# R7FA4L1BD register map
Vendor: Renesas Electronics Corporation; Series: RA4; File version: 0.90.02
CPU: CM33 r0p4, little endian, MPU, FPU, VTOR, 4 interrupt priority bits, 96 interrupts
Registers are 32-bit, read-write, reset 0x0 unless marked. A register's access mark holds for its fields unless they carry their own. Offsets are from the block's base; [hi:lo] are bit positions; {n}, {i} and the like mark numbered series; 'fields as' and 'values as' point back to an identical list.

## UARTA
Base 0x40097000
{0x0+8i} TXBA{i} (i=0..1) 8-bit reset 0xFF — Transmit Buffer Register {i}
{0x1+8i} RXBA{i} (i=0..1) 8-bit ro reset 0xFF — Receive Buffer Register {i}
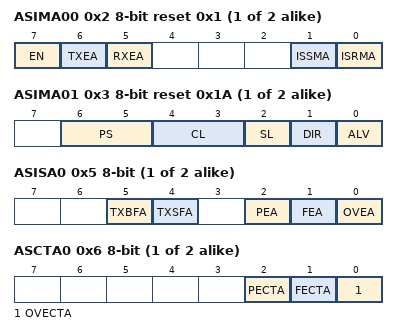
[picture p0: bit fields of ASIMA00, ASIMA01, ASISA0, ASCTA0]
{0x2+8i} ASIMA{i}0 (i=0..1) 8-bit reset 0x1 — Operation Mode Setting Register n0
  [7] EN — UART operation enable
    0=Disables the UART operation clock (resets the internal circuits); 1=Enables the UART operation clock
  [6] TXEA — Transmission enable
    0=Disables transmission (resets the transmission circuit); 1=Enables transmission
  [5] RXEA — Reception enable
    0=Disables reception (reset the reception circuit); 1=Enables reception
  [1] ISSMA — Transmit interrupt mode select
    0=The UARTAn_TXI interrupt is generated on completion of transmission; 1=The UARTAn_TXI interrupt is generated when the transmit buffer becomes empty (for continuous transmission)
  [0] ISRMA — Receive interrupt mode select
    0=The UARTAn_ERI interrupt is generated when a reception error occurs (UARTAn_RXI is not generated); 1=The UARTAn_RXI interrupt is generated when a reception error occurs (UARTAn_ERI is not generated)
{0x3+8i} ASIMA{i}1 (i=0..1) 8-bit reset 0x1A — Operation Mode Setting Register n1
  [6:5] PS — Transmission and reception parity bit setting
    0=Transmission: No parity bit is output. Reception: Data is received without parity.; 1=Transmission: 0 parity is output. Reception: Data is received with 0 parity.; 2=Transmission: Odd parity is output. Reception: Check is made for odd parity.; 3=Transmission: Even parity is output. Reception: Check is made for even parity.
  [4:3] CL — Transmission and reception character length setting
    0=Character length of data = 5 bits; 1=Setting prohibited; 2=Character length of data = 7 bits; 3=Character length of data = 8 bits
  [2] SL — Transmission stop bit length setting
    0=Stop bit length = 1 bit; 1=Stop bit length = 2 bits
  [1] DIR — Transmission and reception order setting
    0=MSB-first; 1=LSB-first
  [0] ALV — Transmission and reception level setting
    0=Positive logic (wait state = high level, start bit = low level, stop bit = high level); 1=Negative logic (wait state = low level, start bit = high level, stop bit = low level)
{0x4+8i} BRGCA{i} (i=0..1) 8-bit reset 0xFF — Baud Rate Generator Control Register {i}
{0x5+8i} ASISA{i} (i=0..1) 8-bit ro — Status Register {i}
  [5] TXBFA — Transmit buffer data flag
    0=No valid data exists in the TXBAn register; 1=Valid data exists in the TXBAn register
  [4] TXSFA — Transmit shift register data flag
    0=Data is not being transmitted; 1=Data is being transmitted
  [2] PEA — Parity error flag
    0=No error has occurred; 1=An error has occurred
  [1] FEA — Framing error flag
    0=No error has occurred; 1=An error has occurred
  [0] OVEA — Overrun error flag
    0=No error has occurred; 1=An error has occurred
{0x6+8i} ASCTA{i} (i=0..1) 8-bit — Status Clear Trigger Register {i}
  [2] PECTA — Parity error flag clear trigger
    0=Does not clear the ASISAn.PEA flag (the flag is retained); 1=Clears the ASISAn.PEA flag
  [1] FECTA — Framing error flag clear trigger
    0=Does not clear the ASISAn.FEA flag (the flag is retained); 1=Clears the ASISAn.FEA flag
  [0] OVECTA — Overrun error flag clear trigger
    0=Does not clear the ASISAn.OVEA flag (the flag is retained); 1=Clears the ASISAn.OVEA flag
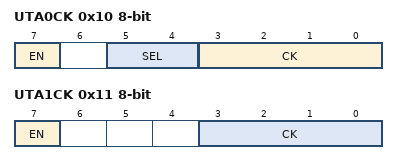
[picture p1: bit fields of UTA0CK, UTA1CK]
0x10 UTA0CK 8-bit — UARTA Clock Select Register 0
  [7] EN
    0=Disables CLKA0 output; 1=Enables CLKA0 output
  [5:4] SEL — fSEL clock select
    0=Stop; 1=UARTAMCLK; 2=UARTAHCLK; 3=UARTAMOCLK
  [3:0] CK — UARTA0 operation clock select (fUTA0)
    0=fSEL; 1=fSEL/2; 2=fSEL/4; 3=fSEL/8; 4=fSEL/16; 5=fSEL/32; 6=fSEL/64; 8=UARTLCLK; 9=UARTSCLK; other=Others (Setting prohibited)
0x11 UTA1CK 8-bit — UARTA Clock Select Register 1
  [7] EN — UARTA1 clock output function enable
    0=Disables CLKA1 output; 1=Enables CLKA1 output
  [3:0] CK — UARTA1 operation clock select (fUTA1)
    values as UTA0CK.CK
